# RL6678_IP_SVD register map
Vendor: Realtek
Registers are 32-bit, read-write, reset 0x0 unless marked. A register's access mark holds for its fields unless they carry their own. Offsets are from the block's base; [hi:lo] are bit positions; lines under a group give offsets from that group; {n}, {i} and the like mark numbered series.

## AON
Base 0x42008000
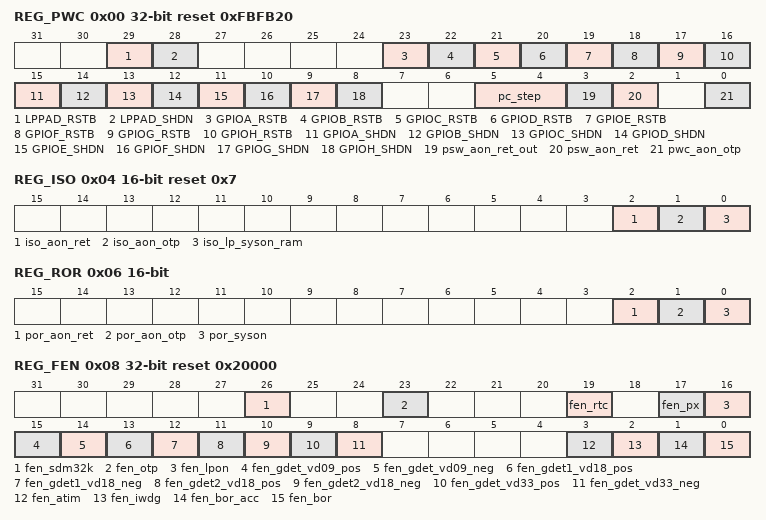
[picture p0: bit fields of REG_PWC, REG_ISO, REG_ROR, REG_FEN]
0x00 REG_PWC access per field reset 0xFBFB20
  [29] LPPAD_RSTB rw — 1: Release LP PAD RSTB33 (except GPIOF) 0: Global Assert LP PAD RSTB33
  [28] LPPAD_SHDN rw — 1: Global Enable LP PAD (except GPIOF) 0: Shutdown LP PAD Note: Default value must be fixed after AON PMC done.
  [23] GPIOA_RSTB rw — 1: Enable GPIOA group pad 0: Reset PAD
  [22] GPIOB_RSTB rw — 1: Enable GPIOA group pad 0: Reset PAD
  [21] GPIOC_RSTB rw — 1: Enable GPIOA group pad 0: Reset PAD This is for audio pad, may not use
  [20] GPIOD_RSTB rw — 1: Enable GPIOA group pad 0: Reset PAD
  [19] GPIOE_RSTB rw — 1: Enable GPIOA group pad 0: Reset PAD
  [18] GPIOF_RSTB rw — 1: Enable GPIOA group pad 0: Reset PAD
  [17] GPIOG_RSTB rw — 1: Enable GPIOA group pad 0: Reset PAD
  [16] GPIOH_RSTB rw — 1: Enable GPIOA group pad 0: Reset PAD
  [15] GPIOA_SHDN rw — 1: Enable GPIOA group pad 0: Shutdown PAD
  [14] GPIOB_SHDN rw — 1: Enable GPIOA group pad 0: Shutdown PAD
  [13] GPIOC_SHDN rw — 1: Enable GPIOA group pad 0: Shutdown PAD This is for audio pad, may not use
  [12] GPIOD_SHDN rw — 1: Enable GPIOA group pad 0: Shutdown PAD
  [11] GPIOE_SHDN rw — 1: Enable GPIOA group pad 0: Shutdown PAD
  [10] GPIOF_SHDN rw — 1: Enable GPIOA group pad 0: Shutdown PAD
  [9] GPIOG_SHDN rw — 1: Enable GPIOA group pad 0: Shutdown PAD
  [8] GPIOH_SHDN rw — 1: Enable GPIOA group pad 0: Shutdown PAD
  [5:4] pc_step rw — power cut enable time step. 0: not valid 1: 10us 2: 20us 3: 30us
  [3] psw_aon_ret_out ro — Aon off domain power switch state ,active 1. 1:it means power enable OK
  [2] psw_aon_ret rw — Aon off domain power switch enable ,active 1. 1:enable 0:disable
  [0] pwc_aon_otp rw — OTP core power cut enable,active 1. for enable, first enable this bit, then enable bit1 for disable, first disable bit 1, then disable this bit 1:enable 0:disable
0x04 REG_ISO 16-bit reset 0x7
  [2] iso_aon_ret — 1: ISO signals from aon off power domain 0: Release
  [1] iso_aon_otp — 1: ISO signals from otp core power domain 0: Release
  [0] iso_lp_syson_ram — When SWR core power on, PD_LP_SYSON_RAM is on. 1: ISO signals from LP SYSON_RAM power domain 0: Release
0x06 REG_ROR 16-bit
  [2] por_aon_ret — 0: reset aon off power domain 1: Release
  [1] por_aon_otp — 0: reset aon otp power domain 1: Release
  [0] por_syson — 0: reset syson power domain 1: Release
0x08 REG_FEN reset 0x20000
  [26] fen_sdm32k — 1: Enable 32.768K SDM function 0: Disable
  [23] fen_otp — 1: Enable OTP function 0: Disable
  [19] fen_rtc — 1: Enable RTC function 0: Disable
  [17] fen_px — 1: Enable pinmux and pad setting 0: Reset
  [16] fen_lpon — LS global reset 1: Enable LS function 0: Disable
  [15] fen_gdet_vd09_pos — 1: Enable glitch detect for swr0p9 posedge 0: disable
  [14] fen_gdet_vd09_neg — 1: Enable glitch detect for swr0p9 negedge 0: disable
  [13] fen_gdet1_vd18_pos — 1: Enable glitch detect for swr psram posedge 0: Reset AON timer
  [12] fen_gdet1_vd18_neg — 1: Enable glitch detect for swr psram negedge 0: disable
  [11] fen_gdet2_vd18_pos — 1: Enable glitch detect for swr mem posedge 0: disable
  [10] fen_gdet2_vd18_neg — 1: Enable glitch detect for swr mem negedge 0: disable
  [9] fen_gdet_vd33_pos — 1: Enable glitch detect for vd33 posedge 0: disable
  [8] fen_gdet_vd33_neg — 1: Enable glitch detect for vd33 negedge 0: disable
  [3] fen_atim — 1: Enable AON timer 0: Reset AON timer Note: AON timer starts to run only when event happens.
  [2] fen_iwdg — 1: Enable IWDG by HW autoload. Once enabled, IWDG can't be disabled unless por asserts.
  [1] fen_bor_acc — Enable high acc bor reset function, default is 0 when power on
  [0] fen_bor — Enable bor reset function, default is 0 when power on
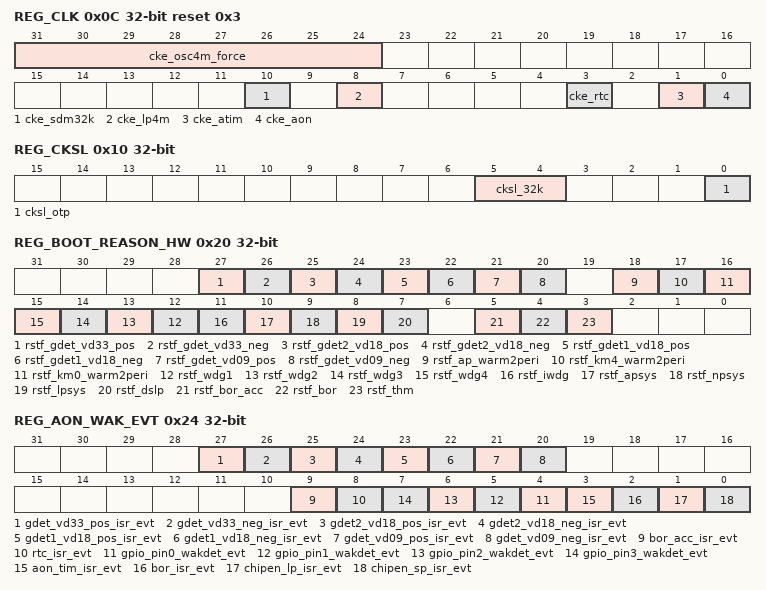
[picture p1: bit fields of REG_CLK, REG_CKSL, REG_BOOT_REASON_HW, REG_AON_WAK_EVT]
0x0C REG_CLK reset 0x3
  [31:24] cke_osc4m_force — [i] = 1 : Force osc4m enable for certain path . [i] = 0 : osc4m enable for certain path is determined by normal control [24]:otpc [25]:aip xtal [26]:peri [27]:platform [28]:VAD [29]:wlan,bt Note, this field is for SW control,[30-31]is retain for SW
  [10] cke_sdm32k — 1: Enable 32.768K SDM module's clock 0: Disable
  [8] cke_lp4m — 1: Enable lp syson plfm 4m clock 0: Disable Note: this bit will set/clr by HW pmc
  [3] cke_rtc — 1: Enable RTC clock 0: Disable
  [1] cke_atim — 1: Enable AON timer clock 0: Disable
  [0] cke_aon — if 1, AON clock will be gated except PMC and this register. Note: AON clock can't be shutdown by analog need.
0x10 REG_CKSL
  [5:4] cksl_32k — This field is used to select 32K clock. 00/01: SDM32K 10: Crystal 32K 11: External 32K
  [0] cksl_otp — This field is used to select OTP clock. 1'b0: AON clock 1'b1: lbus clock (max. 26MHz)
0x20 REG_BOOT_REASON_HW ro
  [27] rstf_gdet_vd33_pos — This bit will be set to 1 when glitch detect vd33 pos happen. Write 1 to clear.
  [26] rstf_gdet_vd33_neg — This bit will be set to 1 when glitch detect vd33 neg happen. Write 1 to clear.
  [25] rstf_gdet2_vd18_pos — This bit will be set to 1 when glitch detect swr mem pos happen. Write 1 to clear.
  [24] rstf_gdet2_vd18_neg — This bit will be set to 1 when glitch detect swr mem neg happen. Write 1 to clear.
  [23] rstf_gdet1_vd18_pos — This bit will be set to 1 when glitch detect swr psram pos happen. Write 1 to clear.
  [22] rstf_gdet1_vd18_neg — This bit will be set to 1 when glitch detect swr psram neg happen. Write 1 to clear.
  [21] rstf_gdet_vd09_pos — This bit will be set to 1 when glitch detect swr core pos happen. Write 1 to clear.
  [20] rstf_gdet_vd09_neg — This bit will be set to 1 when glitch detect swr core neg happen. Write 1 to clear.
  [18] rstf_ap_warm2peri — This bit will be set to 1 when ap warm resets the system. Write 1 to clear.
  [17] rstf_km4_warm2peri — This bit will be set to 1 when km4 warm resets the system. Write 1 to clear.
  [16] rstf_km0_warm2peri — This bit will be set to 1 when km0 warm resets the system. Write 1 to clear.
  [n+11] rstf_wdg{n} (n=1..4) — This bit will be set to 1 when WDG resets the system. Write 1 to clear.
  [11] rstf_iwdg — This bit will be set to 1 when WDG resets the system. Write 1 to clear.
  [10] rstf_apsys — This bit will be set to 1 when CA7 resets the system. Write 1 to clear.
  [9] rstf_npsys — This bit will be set to 1 when KM4 resets the system. Write 1 to clear.
  [8] rstf_lpsys — This bit will be set to 1 when KM0 resets the system. Write 1 to clear.
  [7] rstf_dslp — This is boot reason for dslp exit, clear by SW write to 1.
  [5] rstf_bor_acc — This bit will be set to 1 when BOR ACC resets the system. Write 1 to clear.
  [4] rstf_bor — This bit will be set to 1 when BOR resets the system. Write 1 to clear.
  [3] rstf_thm — This bit will be set to 1 when THERMAL resets the system. Write 1 to clear.
0x24 REG_AON_WAK_EVT ro
  [27] gdet_vd33_pos_isr_evt — glitch detect vd33 pos event happen.
  [26] gdet_vd33_neg_isr_evt — glitch detect vd33 neg event happen.
  [25] gdet2_vd18_pos_isr_evt — glitch detect swr mem pos event happen.
  [24] gdet2_vd18_neg_isr_evt — glitch detect swr mem neg event happen.
  [23] gdet1_vd18_pos_isr_evt — glitch detect swr psram pos event happen.
  [22] gdet1_vd18_neg_isr_evt — glitch detect swr psram neg event happen.
  [21] gdet_vd09_pos_isr_evt — glitch detect swr core pos event happen.
  [20] gdet_vd09_neg_isr_evt — glitch detect swr core neg event happen.
  [9] bor_acc_isr_evt — bor acc interrupt event occurs.
  [8] rtc_isr_evt — RTC interrupt wake event occurs.
  [n+4] gpio_pin{n}_wakdet_evt (n=0..3) — Wake event for wake pin{n} 1: wake event detected 0: no wake event Note: aon gpio only used to wake hw pmc, to interrupt SW, it must enable GPIO interrupt in LP GPIO IP, and the poly must be same as AON GPIO setting.
  [3] aon_tim_isr_evt — AON timer interrupt event occurs.
  [2] bor_isr_evt — bor interrupt event occurs.
  [1] chipen_lp_isr_evt — Chipen long press interrupt event occurs.
  [0] chipen_sp_isr_evt — Chipen short press interrupt event occurs.
0x30 REG_TIM_CNT ro
  [31:0] aon_tim_cnt_cur — Aon timer current count value.
0x34 REG_TIM_SET
  [31:0] aon_tim_cnt_set — Set aon time a countdown value, when timer count down, it will trigger a aon_tim event.
0x38 REG_TIM_IER
  [0] AON_TIM_IE — Timer interrupt enable 0:disable 1:enable
0x3C REG_TIM_ISR ro
  [0] AON_TIM_ISR — Timer interrupt status 0:no interrupt 1:interrupt occurs
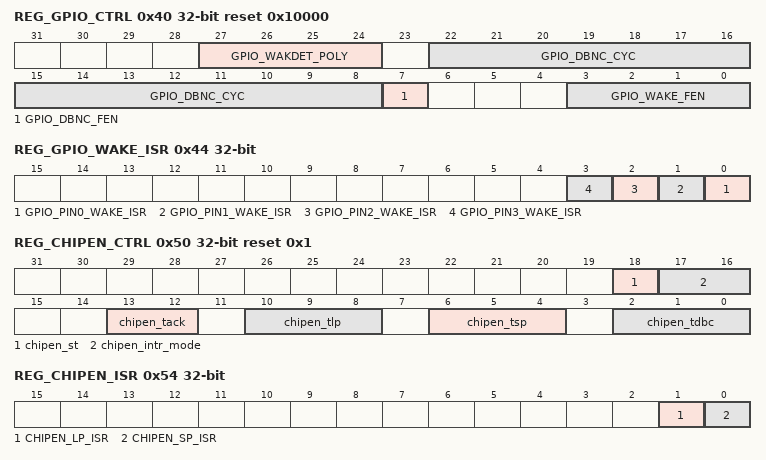
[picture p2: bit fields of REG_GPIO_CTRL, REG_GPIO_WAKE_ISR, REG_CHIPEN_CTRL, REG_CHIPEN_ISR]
0x40 REG_GPIO_CTRL reset 0x10000
  [27:24] GPIO_WAKDET_POLY — Wake pin polarity 0: low active 1: high active bit3: wake pin3 polarity bit2: wake pin2 polarity bit1: wake pin1 polarity bit0: wake pin0 polarity Note: once a wake pin is set, the pads PU/PD will be force by this poly value, and soft config have no use.
  [22:8] GPIO_DBNC_CYC — The GPIO signal will be filtered by the number of debounce cycles of specified in this register. (100k/128k)
  [7] GPIO_DBNC_FEN — 1: Enable gpio debouncer function 0: Disable Default disable for simualtion issue
  [3:0] GPIO_WAKE_FEN — 1: Enable wake pin function 0: Disable Every GPIO has its own enable. When aon pmc is not in DSLP, wake pins will not effect PMC state althrougth this bit is set.
0x44 REG_GPIO_WAKE_ISR ro
  [n] GPIO_PIN{n}_WAKE_ISR (n=0..3) — Wake pin{n} interrupt status 0:no interrupt 1:interrupt occurs
0x50 REG_CHIPEN_CTRL access per field reset 0x1
  [18] chipen_st ro — CHIP_EN pin status 0: logic '0' on CHIP_EN pin 1: logic '1' on CHIP_EN pin
  [17:16] chipen_intr_mode rw — Chipen operation mode. 00: reset mode. When chipen pad low, hw will reset all chip 01: interrup mode. It will enable short/long press function. 1X: pulse reset mode. The transation from other value to 2'd2 will gen a posedge to set RST_PULSE_EN in HV domain. Once in pulse reset mode , this field can't be modified again , and always read out 2'b11
  [13:12] chipen_tack rw — 00: 50ms 01: 100ms 10: 200ms 11: 400ms
  [10:8] chipen_tlp rw — 000: 1000ms 001: 1500ms 010: 2000ms 011: 2500ms 100: 3000ms 101: 3500ms 110: 4000ms 111: 4500ms
  [6:4] chipen_tsp rw — 000: 0ms 001: 50ms 010: 100ms 011: 150ms 100: 200ms 101: 250ms 110: 300ms 111: 350ms
  [2:0] chipen_tdbc rw — 000: 0us 001: 100us 010: 500us 011: 1000us 100: 2000us 101: 4000us 110: 8000us 111: 16000us
0x54 REG_CHIPEN_ISR ro
  [1] CHIPEN_LP_ISR — chipen long press interrupt status 0:no interrupt 1:interrupt occurs
  [0] CHIPEN_SP_ISR — chipen short press interrupt status 0:no interrupt 1:interrupt occurs
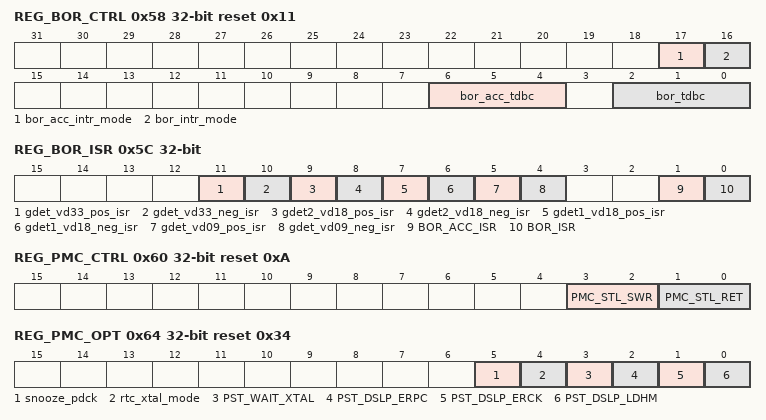
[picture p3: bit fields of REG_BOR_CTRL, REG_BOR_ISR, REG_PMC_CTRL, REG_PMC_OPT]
0x58 REG_BOR_CTRL reset 0x11
  [17] bor_acc_intr_mode — High accuracy BOR operation mode. 0: reset mode. When analog detect bor, hw will trigger a bor reset. 1: interrup mode. It will raise an interrup first. If this bit set to 0, then trigger a bor reset.
  [16] bor_intr_mode — BOR operation mode. 0: reset mode. When analog detect bor, hw will trigger a bor reset. 1: interrup mode. It will raise an interrup first. If this bit set to 0, then trigger a bor reset.
  [6:4] bor_acc_tdbc — 000: 0us 001: 100us 010: 500us 011: 1000us 100: 2000us 101: 4000us 110: 8000us 111: 16000us
  [2:0] bor_tdbc — 000: 0us 001: 100us 010: 500us 011: 1000us 100: 2000us 101: 4000us 110: 8000us 111: 16000us
0x5C REG_BOR_ISR ro
  [11] gdet_vd33_pos_isr — glitch detect vd33 pos interrupt statusen.
  [10] gdet_vd33_neg_isr — glitch detect vd33 neg interrupt statusen.
  [9] gdet2_vd18_pos_isr — glitch detect swr mem pos interrupt statusen.
  [8] gdet2_vd18_neg_isr — glitch detect swr mem neg interrupt statusen.
  [7] gdet1_vd18_pos_isr — glitch detect swr psram pos interrupt statusen.
  [6] gdet1_vd18_neg_isr — glitch detect swr psram neg interrupt statusen.
  [5] gdet_vd09_pos_isr — glitch detect swr core pos interrupt statusen.
  [4] gdet_vd09_neg_isr — glitch detect swr core neg interrupt statusen.
  [1] BOR_ACC_ISR — BOR ACC interrupt status 0:no interrupt 1:interrupt occurs
  [0] BOR_ISR — BOR interrupt status 0:no interrupt 1:interrupt occurs
0x60 REG_PMC_CTRL reset 0xA
  [3:2] PMC_STL_SWR — wait time for SWR stable 0: 64*T (T = 10us) 1: 128*T 2: 256*T 3: 512*T
  [1:0] PMC_STL_RET — wait time after aon ret power switch enable. 0: 32*T (T = 10us) 1: 64*T 2: 128*T 3: 256*T
0x64 REG_PMC_OPT reset 0x34
  [5] snooze_pdck — Select xtal auto pdck function for sdm calibration use xtal lps mode 1:Enable 0:Disable
  [4] rtc_xtal_mode — Select xtal mode when xtal used for sdm calibration. 1: Normal 0: LPS
  [3] PST_WAIT_XTAL — 1: When POF , polling xtal invalid signal and then run forward 0: not polling xtal invalid
  [2] PST_DSLP_ERPC — 1: Enable AON_RET power cut when PMC enter deep-sleep mode 0: Disable
  [1] PST_DSLP_ERCK — 1: Enable 100K clock for AON register access when PMC enter deep-sleep mode 0: Disable
  [0] PST_DSLP_LDHM — 1: Enable AON LDO keep in active mode when PMC enter deep-sleep mode 0: Let AON LDO enter sleep mode when DSLP
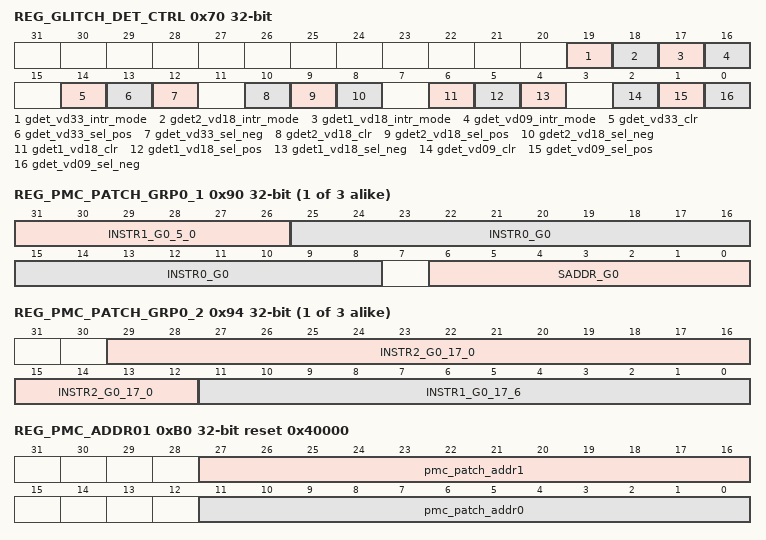
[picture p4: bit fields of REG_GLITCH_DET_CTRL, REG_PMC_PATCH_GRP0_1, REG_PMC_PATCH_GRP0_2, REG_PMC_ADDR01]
0x70 REG_GLITCH_DET_CTRL
  [19] gdet_vd33_intr_mode — gdet vd33 output mode. 0: reset mode. When analog detect event, hw will trigger a bor reset. 1: interrup mode. It will raise an interrup first. If this bit set to 0, then trigger a bor reset.
  [18] gdet2_vd18_intr_mode — gdet swr mem output mode. 0: reset mode. When analog detect event, hw will trigger a bor reset. 1: interrup mode. It will raise an interrup first. If this bit set to 0, then trigger a bor reset.
  [17] gdet1_vd18_intr_mode — gdet swr psram output mode. 0: reset mode. When analog detect event, hw will trigger a bor reset. 1: interrup mode. It will raise an interrup first. If this bit set to 0, then trigger a bor reset.
  [16] gdet_vd09_intr_mode — gdet swr core output mode. 0: reset mode. When analog detect event, hw will trigger a bor reset. 1: interrup mode. It will raise an interrup first. If this bit set to 0, then trigger a bor reset.
  [14] gdet_vd33_clr — 1: clear analog latched detect statue 0: enable analog detect latch Note : this field will auto clear to 0 aftert write 1
  [13] gdet_vd33_sel_pos — gdet voltage select for pos detect
  [12] gdet_vd33_sel_neg — gdet voltage select for net detect
  [10] gdet2_vd18_clr — 1: clear analog latched detect statue 0: enable analog detect latch Note : this field will auto clear to 0 aftert write 1
  [9] gdet2_vd18_sel_pos — gdet voltage select for pos detect
  [8] gdet2_vd18_sel_neg — gdet voltage select for net detect
  [6] gdet1_vd18_clr — 1: clear analog latched detect statue 0: enable analog detect latch Note : this field will auto clear to 0 aftert write 1
  [5] gdet1_vd18_sel_pos — gdet voltage select for pos detect
  [4] gdet1_vd18_sel_neg — gdet voltage select for net detect
  [2] gdet_vd09_clr — 1: clear analog latched detect statue 0: enable analog detect latch Note : this field will auto clear to 0 aftert write 1
  [1] gdet_vd09_sel_pos — gdet voltage select for pos detect
  [0] gdet_vd09_sel_neg — gdet voltage select for net detect
0x80 REG_BOOT_CFG
  [0] DSLP_RETENTION_RAM_PATCH — Deepsleep retention RAM patch
0x84 REG_RSVD_FOR_SW1
  [31:0] dummy
{0x90+8i} REG_PMC_PATCH_GRP{i}_1 (i=0..2)
  [31:26] INSTR1_G{i}_5_0 — Instruction1 of AON PMC patch group{i}
  [25:8] INSTR0_G{i} — Instruction0 of AON PMC patch group{i}
  [6:0] SADDR_G{i} — Start address of the first instruction of AON PMC patch group{i}
{0x94+8i} REG_PMC_PATCH_GRP{i}_2 (i=0..2)
  [29:12] INSTR2_G{i}_17_0 — Instruction2 of AON PMC patch group{i}
  [11:0] INSTR1_G{i}_17_6 — Instruction1 of AON PMC patch group{i}
0xB0 REG_PMC_ADDR01 reset 0x40000
  [27:16] pmc_patch_addr1 — Have used for LPON patch for aon ldo mode chagne SW must initial this bit to 0x10D after power on
  [11:0] pmc_patch_addr0 — Have used for LPON patch for gating km0 and plfm lbus clk both SW initial this field to 0x221 after power on
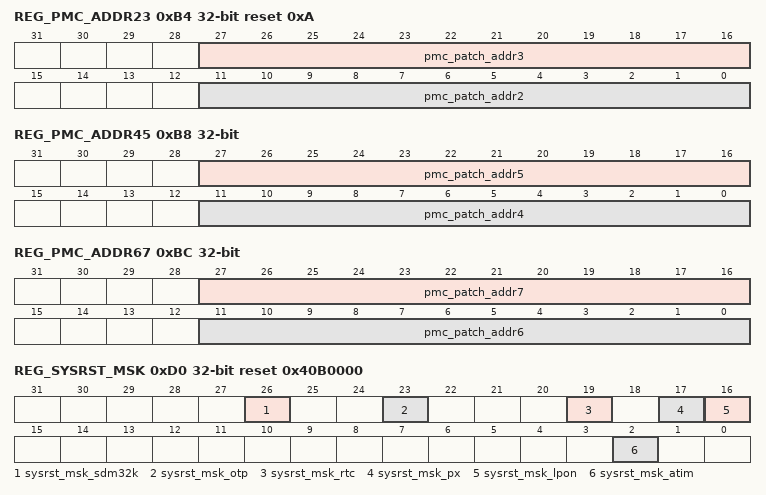
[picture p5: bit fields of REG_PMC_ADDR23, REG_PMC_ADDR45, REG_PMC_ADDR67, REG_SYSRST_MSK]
0xB4 REG_PMC_ADDR23 reset 0xA
  [27:16] pmc_patch_addr3 — HW used only , these are for pmc patch
  [11:0] pmc_patch_addr2 — Have used for LPON patch
0xB8 REG_PMC_ADDR45
  [27:16] pmc_patch_addr5 — HW used only , these are for pmc patch
  [11:0] pmc_patch_addr4 — HW used only , these are for pmc patch
0xBC REG_PMC_ADDR67
  [27:16] pmc_patch_addr7 — HW used only , these are for pmc patch
  [11:0] pmc_patch_addr6 — HW used only , these are for pmc patch
0xD0 REG_SYSRST_MSK reset 0x40B0000
  [26] sysrst_msk_sdm32k — 1: mask 32.768K SDM reset when sys reset happen 0: reset by sys reset
  [23] sysrst_msk_otp — 1: mask OTP reset when sys reset happen 0: reset by sys reset
  [19] sysrst_msk_rtc — 1: mask RTC reset when sys reset happen 0: reset by sys reset
  [17] sysrst_msk_px — 1: mask pinmux and pad setting 0: reset by sys reset
  [16] sysrst_msk_lpon — LS global reset 1: mask LS reset when sys reset happen 0: reset by sys reset
  [2] sysrst_msk_atim — 1: mask AON timer 0: reset by sys reset Note: AON timer starts to run only when event happens.
{0xE0+4i} REG_AON_BACKUP{i} (i=0..3)
  [31:0] dummy
0xF0 REG_BOUNDARY_CHK reset 0xBDC00512
  [31:0] dummy — HW used only . Used for access boundary check, AON is 256B which is 000-FF
0xF4 REG_DUMMY_1F4
  [31:0] dummy — HW used only , these are for reserved
0xF8 REG_DUMMY_1F8 reset 0xFFFFFFFF
  [31:0] dummy — HW used only , these are for reserved
0xFC REG_DUMMY_1FC
  [31:0] dummy — HW used only , these are for reserved [0]: ECO used for pad pupd register save control . 0: normal , 1:save (or retention)
